# CH583SFR register map
Vendor: WCH Ltd.; Series: CH58x; File version: 1.1
WCH wireless MCU CH58x Family Support, Drivers
CPU: RISC-V r0p0, little endian, no MPU, no FPU, 2 interrupt priority bits
Registers are 8-bit, read-write, reset 0x0 unless marked. A register's access mark holds for its fields unless they carry their own. Offsets are from the block's base; lines under a group give offsets from that group; [hi:lo] are bit positions; {n}, {i} and the like mark numbered series; 'fields as' and 'values as' point back to an identical list; <NAME> marks a mode.

## Memory map
0x40001000 SYS size 0x400 — System Control Register
0x40001000 ADC — System Control Register
0x40001000 GPIOA — System Control Register
0x40001000 GPIOB — System Control Register
0x40002000 TMR0 size 0x400 — Timer0 register
0x40002400 TMR1 size 0x400 — Timer1 register
0x40002800 TMR2 size 0x400 — Timer2 register
0x40002C00 TMR3 size 0x400 — Timer3 register
0x40003000 UART0 size 0x400
0x40003400 UART1 size 0x400
0x40003800 UART2 size 0x400
0x40003C00 UART3 size 0x400
0x40004000 SPI0 size 0x400
0x40004400 SPI1 size 0x400
0x40004800 I2C size 0x400
0x40005000 PWMx size 0x400
0x40008000 USB size 0x400
0x40008400 USB2 size 0x400
0xE000E000 PFIC size 0x1000 — Program Fast Interrupt Controller
0xE000F000 Systick size 0x100

## Interrupts
16 TMR0 (SYS, TMR0) — TMR0_IRQHandler
17 GPIOA — GPIO_IRQHandler
18 GPIOB — GPIO_IRQHandler
19 SPI0 (SYS, SPI0) — SPI0_IRQHandler
20 BLEB (SYS) — BB_IRQHandler
21 BLEL (SYS) — LLE_IRQHandler
22 USB (SYS, USB) — USB_IRQHandler
23 USB2 (SYS, USB2) — USB2_IRQHandler
24 TMR1 (SYS, TMR1) — TMR1_IRQHandler
25 TMR2 (SYS, TMR2) — TMR2_IRQHandler
26 UART0 (SYS, UART0) — UART0_IRQHandler
27 UART1 (SYS, UART1) — UART1_IRQHandler
28 RTC (SYS) — RTC_IRQHandler
29 ADC — ADC_IRQHandler
30 I2C (SYS, I2C) — I2C_IRQHandler
31 PWMX_SPI1 (SYS) — PWMX_SPI1_IRQHandler
31 PWMx — PPWMX_SPI1_IRQHandler
31 SPI1 — PPWMX_SPI1_IRQHandler
32 TMR3 (SYS, TMR3) — TMR3_IRQHandler
33 UART2 (SYS, UART2) — UART2_IRQHandler
34 UART3 (SYS, UART3) — UART3_IRQHandler
35 WDOG_BAT (SYS) — WDT_IRQHandler

## ADC — System Control Register
Base 0x40001000
0x58 R8_ADC_CHANNEL reset 0xF — RW, ADC input channel selection
  [3:0] RB_ADC_CH_INX — RW, ADC input channel index
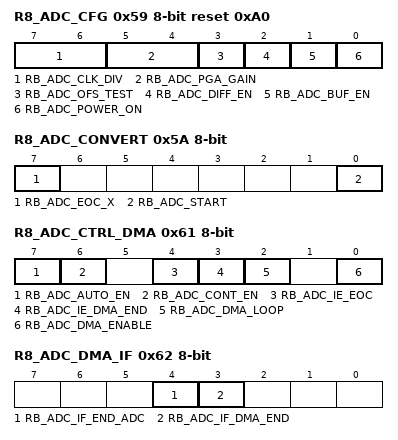
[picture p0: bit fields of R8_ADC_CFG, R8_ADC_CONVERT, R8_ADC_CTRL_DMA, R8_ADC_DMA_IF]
0x59 R8_ADC_CFG reset 0xA0 — RW, ADC configure
  [7:6] RB_ADC_CLK_DIV — RW, select ADC clock frequency: 00=3.2MHz, 01=2.67MHz, 10=5.33MHz, 11=4MHz
  [5:4] RB_ADC_PGA_GAIN — RW, set ADC input PGA gain: 00=-12dB, 01=-6dB, 10=0dB, 11=6dB
  [3] RB_ADC_OFS_TEST — RW, enable ADC offset test mode: 0=normal mode, 1=short to test offset
  [2] RB_ADC_DIFF_EN — RW, ADC input channel mode: 0=single-end, 1=differnetial
  [1] RB_ADC_BUF_EN — RW, ADC input buffer enable
  [0] RB_ADC_POWER_ON — RW, ADC power control: 0=power down, 1=power on
0x5A R8_ADC_CONVERT — RW, ADC convert control
  [7] RB_ADC_EOC_X ro — RO, end of ADC conversion flag
  [0] RB_ADC_START — RW, ADC convert start control: 0=stop ADC convert, 1=start an ADC convert, auto clear
0x5B R8_TEM_SENSOR — RW, temperature sensor control
  [7] RB_TEM_SEN_PWR_ON — RW, temperature sensor power control: 0=power down, 1=power on
0x5C R16_ADC_DATA 16-bit ro — RO, ADC data
  [11:0] RB_ADC_DATA — RO, ADC conversion data
0x5E R8_ADC_INT_FLAG ro — RO, ADC interrupt flag register
  [7] RB_ADC_IF_EOC — RO, ADC conversion interrupt flag: 0=free or converting, 1=end of conversion, interrupt action, write R8_ADC_CONVERT to clear flag
0x60 R32_ADC_DMA_CTRL — RO, ADC DMA control and status register
  [7:0] R32_ADC_DMA_CTRL — RW, ADC DMA enable
0x61 R8_ADC_CTRL_DMA — RW, ADC DMA control
  [7] RB_ADC_AUTO_EN — RW, enable auto continuing ADC for DMA
  [6] RB_ADC_CONT_EN — RW, enable contineous conversion ADC
  [4] RB_ADC_IE_EOC — RW, enable interrupt for end of ADC conversion
  [3] RB_ADC_IE_DMA_END — RW, enable interrupt for ADC DMA completion
  [2] RB_ADC_DMA_LOOP — RW, ADC DMA address loop enable
  [0] RB_ADC_DMA_ENABLE — RW, ADC DMA enable
0x62 R8_ADC_DMA_IF — RO, ADC interrupt flag
  [4] RB_ADC_IF_END_ADC — interrupt flag for end of ADC conversion
  [3] RB_ADC_IF_DMA_END — interrupt flag for ADC DMA completion
0x63 R8_ADC_AUTO_CYCLE — RO, ADC interrupt flag
  [7:0] R8_ADC_AUTO_CYCLE — auto ADC cycle value, unit is 16 Fsys
0x64 R16_ADC_DMA_NOW ro — RO, ADC DMA current address
  [7:0] R16_ADC_DMA_NOW — ADC DMA current address
0x68 R16_ADC_DMA_BEG — RW, ADC DMA begin address
  [7:0] R16_ADC_DMA_BEG — ADC DMA begin address
0x6C R16_ADC_DMA_END — RW, ADC DMA end address
  [7:0] R16_ADC_DMA_END — ADC DMA end address
